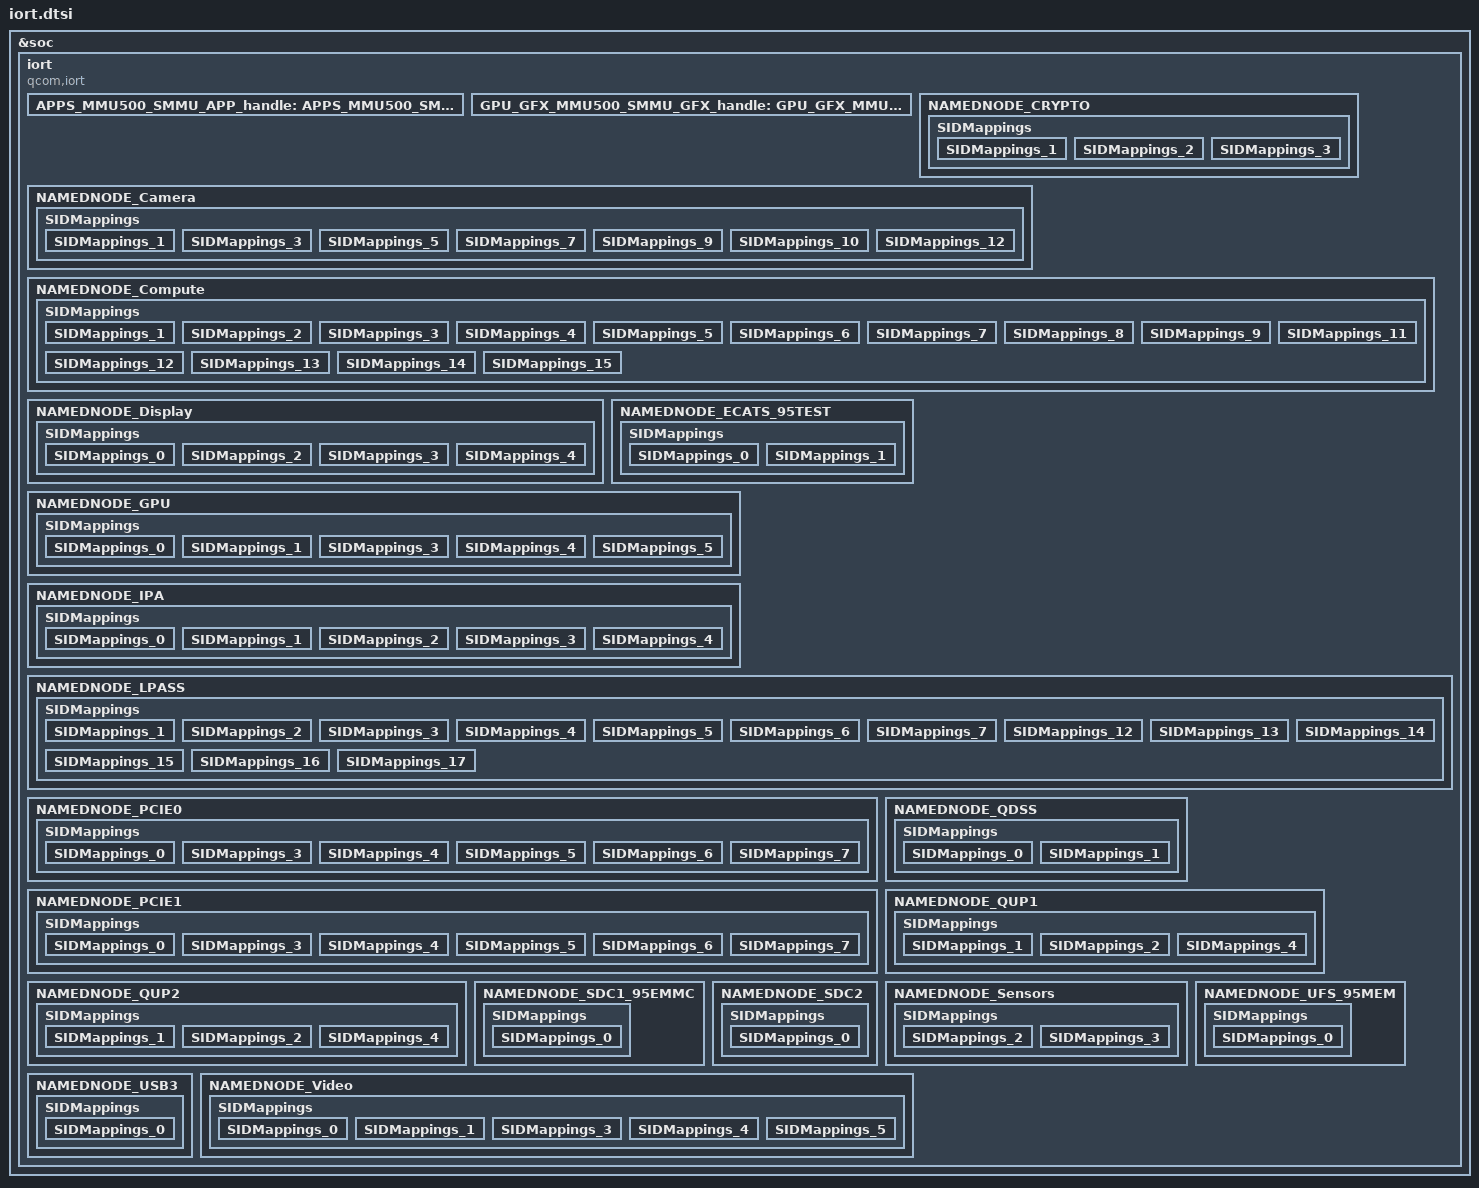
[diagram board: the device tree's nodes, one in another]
/** SMMU IORT Device Tree for milos_1.0.

This file is automatically generated.
SMMU Base Address and Span information based on Chip Version: milos_v1.0_p3q2r36_F02.
Interrupt information based on Interrupt Map Version: milos_v1.0_p3q1r23_09_22_DV_Patch.
SMMU SID Mappings based on http://ipcatalog.qualcomm.com/hsr/3393 - Milos_SID_Sheet.xlsx Version 6.0.

Copyright (c) 2023 Qualcomm Technologies, Inc.
All Rights Reserved.
Confidential and Proprietary - Qualcomm Technologies, Inc.
*/

#include <iort_defines.h>
&soc{
  iort {
    compatible = "qcom,iort";
    Signature = <0x54524F49>;
    Revision = <1>;
    Checksum = <0>;
    OEMID = ACPI_OEM_ID;
    OEMTableID = <ACPI_OEM_TABLE_ID>;
    OEMRevision = <ACPI_OEM_REVISION>;
    CreatorID = <ACPI_CREATOR_ID>;
    CreatorRevision = <ACPI_CREATOR_REVISION>;
    NumberofIORTNodes = <21>;
    Reserved = <0>;
    instance_handles = < &APPS_MMU500_SMMU_APP_handle  &GPU_GFX_MMU500_SMMU_GFX_handle >;
    
    APPS_MMU500_SMMU_APP_handle:APPS_MMU500_SMMU_APP {
      Type = <3>;
      Revision = <1>;
      Reserved = <0>;
      NumberofMappings = <0>;
      BaseAddress = <0x15000000>; 
      Span = <0x00080000>; 
      Flags = <3>;
      Model = <3>;
      NumContextInterrupts = <96>;
      NumPMUInterrupts = <0>;
      NSGIRPT_GSIV = <97>;
      NSGIRPT_FLAGS = <0>;
      NSGCFGIRPT_GSIV = <0>;
      NSGCFGIRPT_FLAGS = <0>;
      ContextInterrupts = <129 130 131 132 133 134 135 136 137 138 139 140 141 142 143 144 145 146 147 148 149 150 213 214 215 216 217 218 219 220 221 222 223 224 347 348 349 350 351 352 353 354 355 356 357 358 359 360 361 362 363 364 365 366 367 368 369 370 371 372 373 374 375 376 377 427 428 429 430 431 432 433 434 435 436 437 438 439 440 441 450 451 444 453 738 455 456 457 721 722 723 724 725 726 727 728 >;
      ContextInterruptFlags = <0 0 0 0 0 0 0 0 0 0 0 0 0 0 0 0 0 0 0 0 0 0 0 0 0 0 0 0 0 0 0 0 0 0 0 0 0 0 0 0 0 0 0 0 0 0 0 0 0 0 0 0 0 0 0 0 0 0 0 0 0 0 0 0 0 0 0 0 0 0 0 0 0 0 0 0 0 0 0 0 0 0 0 0 0 0 0 0 0 0 0 0 0 0 0 0 >;
      PMUInterrupts = <0 >;
      PMUInterruptFlags = <0 >;
      SIDMAPPING =<0>;
      };
    GPU_GFX_MMU500_SMMU_GFX_handle:GPU_GFX_MMU500_SMMU_GFX {
      Type = <3>;
      Revision = <1>;
      Reserved = <0>;
      NumberofMappings = <0>;
      BaseAddress = <0x03da0000>; 
      Span = <0x00020000>; 
      Flags = <3>;
      Model = <3>;
      NumContextInterrupts = <25>;
      NumPMUInterrupts = <0>;
      NSGIRPT_GSIV = <705>;
      NSGIRPT_FLAGS = <0>;
      NSGCFGIRPT_GSIV = <0>;
      NSGCFGIRPT_FLAGS = <0>;
      ContextInterrupts = <709 710 711 712 713 714 715 716 717 718 719 454 508 606 607 608 609 691 693 696 697 698 700 701 731 >;
      ContextInterruptFlags = <0 0 0 0 0 0 0 0 0 0 0 0 0 0 0 0 0 0 0 0 0 0 0 0 0 >;
      PMUInterrupts = <0 >;
      PMUInterruptFlags = <0 >;
      SIDMAPPING =<0>;
      };
    
    
    NAMEDNODE_CRYPTO {
      Type = <1>;
      Revision = <1>;
      Reserved = <0>;
      NumberofMappings = <3>;
      NodeFlags = <0>;
      CacheCoherency = <0>;
      AllocationHints = <0>;
      Reserved1 = <0>;
      MemAccessFlags = <0>;
      DeviceMemAddressSize = <36>;
      DevObjectName = "CRYPTO";
      SIDMappings {
        SIDMappings_1 {
          InputBase = <(
              (IORT_WORLD_ID_NON_SECURE << IORT_WORLD_ID_SHIFT) |
              (IORT_DYNAMIC_MAPPING_NO << IORT_DYNAMIC_MAPPING_SHIFT) |
              (IORT_TRANSLATION_TYPE_NESTED << IORT_TRANSLATION_TYPE_SHIFT) |
              (1))>;
          NumIDs = <1>;
          OutputBase = <0x00000481>;
          Flags = <0>;
          OutputReference = <&APPS_MMU500_SMMU_APP_handle>;
        };
        SIDMappings_2 {
          InputBase = <(
              (IORT_WORLD_ID_NON_SECURE << IORT_WORLD_ID_SHIFT) |
              (IORT_DYNAMIC_MAPPING_NO << IORT_DYNAMIC_MAPPING_SHIFT) |
              (IORT_TRANSLATION_TYPE_NESTED << IORT_TRANSLATION_TYPE_SHIFT) |
              (2))>;
          NumIDs = <1>;
          OutputBase = <0x00000480>;
          Flags = <0>;
          OutputReference = <&APPS_MMU500_SMMU_APP_handle>;
        };
        SIDMappings_3 {
          InputBase = <(
              (IORT_WORLD_ID_NON_SECURE << IORT_WORLD_ID_SHIFT) |
              (IORT_DYNAMIC_MAPPING_NO << IORT_DYNAMIC_MAPPING_SHIFT) |
              (IORT_TRANSLATION_TYPE_NESTED << IORT_TRANSLATION_TYPE_SHIFT) |
              (3))>;
          NumIDs = <1>;
          OutputBase = <0x00000483>;
          Flags = <0>;
          OutputReference = <&APPS_MMU500_SMMU_APP_handle>;
        };
      };
    };
    NAMEDNODE_Camera {
      Type = <1>;
      Revision = <1>;
      Reserved = <0>;
      NumberofMappings = <7>;
      NodeFlags = <0>;
      CacheCoherency = <0>;
      AllocationHints = <0>;
      Reserved1 = <0>;
      MemAccessFlags = <0>;
      DeviceMemAddressSize = <36>;
      DevObjectName = "CAMERA";
      SIDMappings {
        SIDMappings_1 {
          InputBase = <(
              (IORT_WORLD_ID_NON_SECURE << IORT_WORLD_ID_SHIFT) |
              (IORT_DYNAMIC_MAPPING_NO << IORT_DYNAMIC_MAPPING_SHIFT) |
              (IORT_TRANSLATION_TYPE_NESTED << IORT_TRANSLATION_TYPE_SHIFT) |
              (1))>;
          NumIDs = <1>;
          OutputBase = <0x00a01840>;
          Flags = <0>;
          OutputReference = <&APPS_MMU500_SMMU_APP_handle>;
        };
        SIDMappings_3 {
          InputBase = <(
              (IORT_WORLD_ID_NON_SECURE << IORT_WORLD_ID_SHIFT) |
              (IORT_DYNAMIC_MAPPING_NO << IORT_DYNAMIC_MAPPING_SHIFT) |
              (IORT_TRANSLATION_TYPE_NESTED << IORT_TRANSLATION_TYPE_SHIFT) |
              (3))>;
          NumIDs = <1>;
          OutputBase = <0x00001800>;
          Flags = <0>;
          OutputReference = <&APPS_MMU500_SMMU_APP_handle>;
        };
        SIDMappings_5 {
          InputBase = <(
              (IORT_WORLD_ID_NON_SECURE << IORT_WORLD_ID_SHIFT) |
              (IORT_DYNAMIC_MAPPING_NO << IORT_DYNAMIC_MAPPING_SHIFT) |
              (IORT_TRANSLATION_TYPE_NESTED << IORT_TRANSLATION_TYPE_SHIFT) |
              (5))>;
          NumIDs = <1>;
          OutputBase = <0x00001820>;
          Flags = <0>;
          OutputReference = <&APPS_MMU500_SMMU_APP_handle>;
        };
        SIDMappings_7 {
          InputBase = <(
              (IORT_WORLD_ID_NON_SECURE << IORT_WORLD_ID_SHIFT) |
              (IORT_DYNAMIC_MAPPING_NO << IORT_DYNAMIC_MAPPING_SHIFT) |
              (IORT_TRANSLATION_TYPE_NESTED << IORT_TRANSLATION_TYPE_SHIFT) |
              (7))>;
          NumIDs = <1>;
          OutputBase = <0x00001900>;
          Flags = <0>;
          OutputReference = <&APPS_MMU500_SMMU_APP_handle>;
        };
        SIDMappings_9 {
          InputBase = <(
              (IORT_WORLD_ID_NON_SECURE << IORT_WORLD_ID_SHIFT) |
              (IORT_DYNAMIC_MAPPING_NO << IORT_DYNAMIC_MAPPING_SHIFT) |
              (IORT_TRANSLATION_TYPE_NESTED << IORT_TRANSLATION_TYPE_SHIFT) |
              (9))>;
          NumIDs = <1>;
          OutputBase = <0x00001920>;
          Flags = <0>;
          OutputReference = <&APPS_MMU500_SMMU_APP_handle>;
        };
        SIDMappings_10 {
          InputBase = <(
              (IORT_WORLD_ID_NON_SECURE << IORT_WORLD_ID_SHIFT) |
              (IORT_DYNAMIC_MAPPING_NO << IORT_DYNAMIC_MAPPING_SHIFT) |
              (IORT_TRANSLATION_TYPE_NESTED << IORT_TRANSLATION_TYPE_SHIFT) |
              (10))>;
          NumIDs = <1>;
          OutputBase = <0x00001940>;
          Flags = <0>;
          OutputReference = <&APPS_MMU500_SMMU_APP_handle>;
        };
        SIDMappings_12 {
          InputBase = <(
              (IORT_WORLD_ID_NON_SECURE << IORT_WORLD_ID_SHIFT) |
              (IORT_DYNAMIC_MAPPING_NO << IORT_DYNAMIC_MAPPING_SHIFT) |
              (IORT_TRANSLATION_TYPE_NESTED << IORT_TRANSLATION_TYPE_SHIFT) |
              (12))>;
          NumIDs = <1>;
          OutputBase = <0x00200880>;
          Flags = <0>;
          OutputReference = <&APPS_MMU500_SMMU_APP_handle>;
        };
      };
    };
    NAMEDNODE_Compute {
      Type = <1>;
      Revision = <1>;
      Reserved = <0>;
      NumberofMappings = <14>;
      NodeFlags = <0>;
      CacheCoherency = <0>;
      AllocationHints = <0>;
      Reserved1 = <0>;
      MemAccessFlags = <0>;
      DeviceMemAddressSize = <36>;
      DevObjectName = "COMPUTE";
      SIDMappings {
        SIDMappings_1 {
          InputBase = <(
              (IORT_WORLD_ID_NON_SECURE << IORT_WORLD_ID_SHIFT) |
              (IORT_DYNAMIC_MAPPING_NO << IORT_DYNAMIC_MAPPING_SHIFT) |
              (IORT_TRANSLATION_TYPE_NESTED << IORT_TRANSLATION_TYPE_SHIFT) |
              (1))>;
          NumIDs = <1>;
          OutputBase = <0x00000c01>;
          Flags = <0>;
          OutputReference = <&APPS_MMU500_SMMU_APP_handle>;
        };
        SIDMappings_2 {
          InputBase = <(
              (IORT_WORLD_ID_NON_SECURE << IORT_WORLD_ID_SHIFT) |
              (IORT_DYNAMIC_MAPPING_NO << IORT_DYNAMIC_MAPPING_SHIFT) |
              (IORT_TRANSLATION_TYPE_NESTED << IORT_TRANSLATION_TYPE_SHIFT) |
              (2))>;
          NumIDs = <1>;
          OutputBase = <0x00000c02>;
          Flags = <0>;
          OutputReference = <&APPS_MMU500_SMMU_APP_handle>;
        };
        SIDMappings_3 {
          InputBase = <(
              (IORT_WORLD_ID_NON_SECURE << IORT_WORLD_ID_SHIFT) |
              (IORT_DYNAMIC_MAPPING_NO << IORT_DYNAMIC_MAPPING_SHIFT) |
              (IORT_TRANSLATION_TYPE_NESTED << IORT_TRANSLATION_TYPE_SHIFT) |
              (3))>;
          NumIDs = <1>;
          OutputBase = <0x00000c03>;
          Flags = <0>;
          OutputReference = <&APPS_MMU500_SMMU_APP_handle>;
        };
        SIDMappings_4 {
          InputBase = <(
              (IORT_WORLD_ID_NON_SECURE << IORT_WORLD_ID_SHIFT) |
              (IORT_DYNAMIC_MAPPING_NO << IORT_DYNAMIC_MAPPING_SHIFT) |
              (IORT_TRANSLATION_TYPE_NESTED << IORT_TRANSLATION_TYPE_SHIFT) |
              (4))>;
          NumIDs = <1>;
          OutputBase = <0x00000c04>;
          Flags = <0>;
          OutputReference = <&APPS_MMU500_SMMU_APP_handle>;
        };
        SIDMappings_5 {
          InputBase = <(
              (IORT_WORLD_ID_NON_SECURE << IORT_WORLD_ID_SHIFT) |
              (IORT_DYNAMIC_MAPPING_NO << IORT_DYNAMIC_MAPPING_SHIFT) |
              (IORT_TRANSLATION_TYPE_NESTED << IORT_TRANSLATION_TYPE_SHIFT) |
              (5))>;
          NumIDs = <1>;
          OutputBase = <0x00000c05>;
          Flags = <0>;
          OutputReference = <&APPS_MMU500_SMMU_APP_handle>;
        };
        SIDMappings_6 {
          InputBase = <(
              (IORT_WORLD_ID_NON_SECURE << IORT_WORLD_ID_SHIFT) |
              (IORT_DYNAMIC_MAPPING_NO << IORT_DYNAMIC_MAPPING_SHIFT) |
              (IORT_TRANSLATION_TYPE_NESTED << IORT_TRANSLATION_TYPE_SHIFT) |
              (6))>;
          NumIDs = <1>;
          OutputBase = <0x00000c06>;
          Flags = <0>;
          OutputReference = <&APPS_MMU500_SMMU_APP_handle>;
        };
        SIDMappings_7 {
          InputBase = <(
              (IORT_WORLD_ID_NON_SECURE << IORT_WORLD_ID_SHIFT) |
              (IORT_DYNAMIC_MAPPING_NO << IORT_DYNAMIC_MAPPING_SHIFT) |
              (IORT_TRANSLATION_TYPE_NESTED << IORT_TRANSLATION_TYPE_SHIFT) |
              (7))>;
          NumIDs = <1>;
          OutputBase = <0x00000c07>;
          Flags = <0>;
          OutputReference = <&APPS_MMU500_SMMU_APP_handle>;
        };
        SIDMappings_8 {
          InputBase = <(
              (IORT_WORLD_ID_NON_SECURE << IORT_WORLD_ID_SHIFT) |
              (IORT_DYNAMIC_MAPPING_NO << IORT_DYNAMIC_MAPPING_SHIFT) |
              (IORT_TRANSLATION_TYPE_NESTED << IORT_TRANSLATION_TYPE_SHIFT) |
              (8))>;
          NumIDs = <1>;
          OutputBase = <0x00000c08>;
          Flags = <0>;
          OutputReference = <&APPS_MMU500_SMMU_APP_handle>;
        };
        SIDMappings_9 {
          InputBase = <(
              (IORT_WORLD_ID_NON_SECURE << IORT_WORLD_ID_SHIFT) |
              (IORT_DYNAMIC_MAPPING_NO << IORT_DYNAMIC_MAPPING_SHIFT) |
              (IORT_TRANSLATION_TYPE_NESTED << IORT_TRANSLATION_TYPE_SHIFT) |
              (9))>;
          NumIDs = <1>;
          OutputBase = <0x00000c09>;
          Flags = <0>;
          OutputReference = <&APPS_MMU500_SMMU_APP_handle>;
        };
        SIDMappings_11 {
          InputBase = <(
              (IORT_WORLD_ID_NON_SECURE << IORT_WORLD_ID_SHIFT) |
              (IORT_DYNAMIC_MAPPING_NO << IORT_DYNAMIC_MAPPING_SHIFT) |
              (IORT_TRANSLATION_TYPE_NESTED << IORT_TRANSLATION_TYPE_SHIFT) |
              (11))>;
          NumIDs = <1>;
          OutputBase = <0x00000c0b>;
          Flags = <0>;
          OutputReference = <&APPS_MMU500_SMMU_APP_handle>;
        };
        SIDMappings_12 {
          InputBase = <(
              (IORT_WORLD_ID_NON_SECURE << IORT_WORLD_ID_SHIFT) |
              (IORT_DYNAMIC_MAPPING_NO << IORT_DYNAMIC_MAPPING_SHIFT) |
              (IORT_TRANSLATION_TYPE_NESTED << IORT_TRANSLATION_TYPE_SHIFT) |
              (12))>;
          NumIDs = <1>;
          OutputBase = <0x00000c0c>;
          Flags = <0>;
          OutputReference = <&APPS_MMU500_SMMU_APP_handle>;
        };
        SIDMappings_13 {
          InputBase = <(
              (IORT_WORLD_ID_NON_SECURE << IORT_WORLD_ID_SHIFT) |
              (IORT_DYNAMIC_MAPPING_NO << IORT_DYNAMIC_MAPPING_SHIFT) |
              (IORT_TRANSLATION_TYPE_NESTED << IORT_TRANSLATION_TYPE_SHIFT) |
              (13))>;
          NumIDs = <1>;
          OutputBase = <0x00000c0d>;
          Flags = <0>;
          OutputReference = <&APPS_MMU500_SMMU_APP_handle>;
        };
        SIDMappings_14 {
          InputBase = <(
              (IORT_WORLD_ID_NON_SECURE << IORT_WORLD_ID_SHIFT) |
              (IORT_DYNAMIC_MAPPING_NO << IORT_DYNAMIC_MAPPING_SHIFT) |
              (IORT_TRANSLATION_TYPE_NESTED << IORT_TRANSLATION_TYPE_SHIFT) |
              (14))>;
          NumIDs = <1>;
          OutputBase = <0x00000c0e>;
          Flags = <0>;
          OutputReference = <&APPS_MMU500_SMMU_APP_handle>;
        };
        SIDMappings_15 {
          InputBase = <(
              (IORT_WORLD_ID_NON_SECURE << IORT_WORLD_ID_SHIFT) |
              (IORT_DYNAMIC_MAPPING_NO << IORT_DYNAMIC_MAPPING_SHIFT) |
              (IORT_TRANSLATION_TYPE_NESTED << IORT_TRANSLATION_TYPE_SHIFT) |
              (15))>;
          NumIDs = <1>;
          OutputBase = <0x00000c0f>;
          Flags = <0>;
          OutputReference = <&APPS_MMU500_SMMU_APP_handle>;
        };
      };
    };
    NAMEDNODE_Display {
      Type = <1>;
      Revision = <1>;
      Reserved = <0>;
      NumberofMappings = <4>;
      NodeFlags = <0>;
      CacheCoherency = <0>;
      AllocationHints = <0>;
      Reserved1 = <0>;
      MemAccessFlags = <0>;
      DeviceMemAddressSize = <36>;
      DevObjectName = "DISPLAY";
      SIDMappings {
        SIDMappings_0 {
          InputBase = <(
              (IORT_WORLD_ID_NON_SECURE << IORT_WORLD_ID_SHIFT) |
              (IORT_DYNAMIC_MAPPING_NO << IORT_DYNAMIC_MAPPING_SHIFT) |
              (IORT_TRANSLATION_TYPE_NESTED << IORT_TRANSLATION_TYPE_SHIFT) |
              (0))>;
          NumIDs = <1>;
          OutputBase = <0x00021c00>;
          Flags = <0>;
          OutputReference = <&APPS_MMU500_SMMU_APP_handle>;
        };
        SIDMappings_2 {
          InputBase = <(
              (IORT_WORLD_ID_NON_SECURE << IORT_WORLD_ID_SHIFT) |
              (IORT_DYNAMIC_MAPPING_YES_DEFAULT << IORT_DYNAMIC_MAPPING_SHIFT) |
              (IORT_TRANSLATION_TYPE_NESTED << IORT_TRANSLATION_TYPE_SHIFT) |
              (2))>;
          NumIDs = <1>;
          OutputBase = <0x00001c01>;
          Flags = <0>;
          OutputReference = <&APPS_MMU500_SMMU_APP_handle>;
        };
        SIDMappings_3 {
          InputBase = <(
              (IORT_WORLD_ID_NON_SECURE << IORT_WORLD_ID_SHIFT) |
              (IORT_DYNAMIC_MAPPING_NO << IORT_DYNAMIC_MAPPING_SHIFT) |
              (IORT_TRANSLATION_TYPE_NESTED << IORT_TRANSLATION_TYPE_SHIFT) |
              (3))>;
          NumIDs = <1>;
          OutputBase = <0x00001c03>;
          Flags = <0>;
          OutputReference = <&APPS_MMU500_SMMU_APP_handle>;
        };
        SIDMappings_4 {
          InputBase = <(
              (IORT_WORLD_ID_NON_SECURE << IORT_WORLD_ID_SHIFT) |
              (IORT_DYNAMIC_MAPPING_NO << IORT_DYNAMIC_MAPPING_SHIFT) |
              (IORT_TRANSLATION_TYPE_NESTED << IORT_TRANSLATION_TYPE_SHIFT) |
              (4))>;
          NumIDs = <1>;
          OutputBase = <0x00021c04>;
          Flags = <0>;
          OutputReference = <&APPS_MMU500_SMMU_APP_handle>;
        };
      };
    };
    NAMEDNODE_ECATS_95TEST {
      Type = <1>;
      Revision = <1>;
      Reserved = <0>;
      NumberofMappings = <2>;
      NodeFlags = <0>;
      CacheCoherency = <0>;
      AllocationHints = <0>;
      Reserved1 = <0>;
      MemAccessFlags = <0>;
      DeviceMemAddressSize = <36>;
      DevObjectName = "ECATS_TEST";
      SIDMappings {
        SIDMappings_0 {
          InputBase = <(
              (IORT_WORLD_ID_NON_SECURE << IORT_WORLD_ID_SHIFT) |
              (IORT_DYNAMIC_MAPPING_NO << IORT_DYNAMIC_MAPPING_SHIFT) |
              (IORT_TRANSLATION_TYPE_NESTED << IORT_TRANSLATION_TYPE_SHIFT) |
              (0))>;
          NumIDs = <1>;
          OutputBase = <0x00000400>;
          Flags = <0>;
          OutputReference = <&APPS_MMU500_SMMU_APP_handle>;
        };
        SIDMappings_1 {
          InputBase = <(
              (IORT_WORLD_ID_NON_SECURE << IORT_WORLD_ID_SHIFT) |
              (IORT_DYNAMIC_MAPPING_NO << IORT_DYNAMIC_MAPPING_SHIFT) |
              (IORT_TRANSLATION_TYPE_NESTED << IORT_TRANSLATION_TYPE_SHIFT) |
              (1))>;
          NumIDs = <1>;
          OutputBase = <0x00000401>;
          Flags = <0>;
          OutputReference = <&APPS_MMU500_SMMU_APP_handle>;
        };
      };
    };
    NAMEDNODE_GPU {
      Type = <1>;
      Revision = <1>;
      Reserved = <0>;
      NumberofMappings = <5>;
      NodeFlags = <0>;
      CacheCoherency = <0>;
      AllocationHints = <0>;
      Reserved1 = <0>;
      MemAccessFlags = <0>;
      DeviceMemAddressSize = <36>;
      DevObjectName = "GPU";
      SIDMappings {
        SIDMappings_0 {
          InputBase = <(
              (IORT_WORLD_ID_NON_SECURE << IORT_WORLD_ID_SHIFT) |
              (IORT_DYNAMIC_MAPPING_NO << IORT_DYNAMIC_MAPPING_SHIFT) |
              (IORT_TRANSLATION_TYPE_NESTED << IORT_TRANSLATION_TYPE_SHIFT) |
              (0))>;
          NumIDs = <1>;
          OutputBase = <0x00000000>;
          Flags = <0>;
          OutputReference = <&GPU_GFX_MMU500_SMMU_GFX_handle>;
        };
        SIDMappings_1 {
          InputBase = <(
              (IORT_WORLD_ID_NON_SECURE << IORT_WORLD_ID_SHIFT) |
              (IORT_DYNAMIC_MAPPING_NO << IORT_DYNAMIC_MAPPING_SHIFT) |
              (IORT_TRANSLATION_TYPE_NESTED << IORT_TRANSLATION_TYPE_SHIFT) |
              (1))>;
          NumIDs = <1>;
          OutputBase = <0x00000002>;
          Flags = <0>;
          OutputReference = <&GPU_GFX_MMU500_SMMU_GFX_handle>;
        };
        SIDMappings_3 {
          InputBase = <(
              (IORT_WORLD_ID_NON_SECURE << IORT_WORLD_ID_SHIFT) |
              (IORT_DYNAMIC_MAPPING_NO << IORT_DYNAMIC_MAPPING_SHIFT) |
              (IORT_TRANSLATION_TYPE_NESTED << IORT_TRANSLATION_TYPE_SHIFT) |
              (3))>;
          NumIDs = <1>;
          OutputBase = <0x00000004>;
          Flags = <0>;
          OutputReference = <&GPU_GFX_MMU500_SMMU_GFX_handle>;
        };
        SIDMappings_4 {
          InputBase = <(
              (IORT_WORLD_ID_NON_SECURE << IORT_WORLD_ID_SHIFT) |
              (IORT_DYNAMIC_MAPPING_NO << IORT_DYNAMIC_MAPPING_SHIFT) |
              (IORT_TRANSLATION_TYPE_NESTED << IORT_TRANSLATION_TYPE_SHIFT) |
              (4))>;
          NumIDs = <1>;
          OutputBase = <0x00000005>;
          Flags = <0>;
          OutputReference = <&GPU_GFX_MMU500_SMMU_GFX_handle>;
        };
        SIDMappings_5 {
          InputBase = <(
              (IORT_WORLD_ID_NON_SECURE << IORT_WORLD_ID_SHIFT) |
              (IORT_DYNAMIC_MAPPING_NO << IORT_DYNAMIC_MAPPING_SHIFT) |
              (IORT_TRANSLATION_TYPE_NESTED << IORT_TRANSLATION_TYPE_SHIFT) |
              (5))>;
          NumIDs = <1>;
          OutputBase = <0x00000007>;
          Flags = <0>;
          OutputReference = <&GPU_GFX_MMU500_SMMU_GFX_handle>;
        };
      };
    };
    NAMEDNODE_IPA {
      Type = <1>;
      Revision = <1>;
      Reserved = <0>;
      NumberofMappings = <5>;
      NodeFlags = <0>;
      CacheCoherency = <0>;
      AllocationHints = <0>;
      Reserved1 = <0>;
      MemAccessFlags = <0>;
      DeviceMemAddressSize = <36>;
      DevObjectName = "IPA";
      SIDMappings {
        SIDMappings_0 {
          InputBase = <(
              (IORT_WORLD_ID_NON_SECURE << IORT_WORLD_ID_SHIFT) |
              (IORT_DYNAMIC_MAPPING_NO << IORT_DYNAMIC_MAPPING_SHIFT) |
              (IORT_TRANSLATION_TYPE_NESTED << IORT_TRANSLATION_TYPE_SHIFT) |
              (0))>;
          NumIDs = <1>;
          OutputBase = <0x000004a0>;
          Flags = <0>;
          OutputReference = <&APPS_MMU500_SMMU_APP_handle>;
        };
        SIDMappings_1 {
          InputBase = <(
              (IORT_WORLD_ID_NON_SECURE << IORT_WORLD_ID_SHIFT) |
              (IORT_DYNAMIC_MAPPING_NO << IORT_DYNAMIC_MAPPING_SHIFT) |
              (IORT_TRANSLATION_TYPE_NESTED << IORT_TRANSLATION_TYPE_SHIFT) |
              (1))>;
          NumIDs = <1>;
          OutputBase = <0x000004a1>;
          Flags = <0>;
          OutputReference = <&APPS_MMU500_SMMU_APP_handle>;
        };
        SIDMappings_2 {
          InputBase = <(
              (IORT_WORLD_ID_NON_SECURE << IORT_WORLD_ID_SHIFT) |
              (IORT_DYNAMIC_MAPPING_NO << IORT_DYNAMIC_MAPPING_SHIFT) |
              (IORT_TRANSLATION_TYPE_NESTED << IORT_TRANSLATION_TYPE_SHIFT) |
              (2))>;
          NumIDs = <1>;
          OutputBase = <0x000004a2>;
          Flags = <0>;
          OutputReference = <&APPS_MMU500_SMMU_APP_handle>;
        };
        SIDMappings_3 {
          InputBase = <(
              (IORT_WORLD_ID_NON_SECURE << IORT_WORLD_ID_SHIFT) |
              (IORT_DYNAMIC_MAPPING_NO << IORT_DYNAMIC_MAPPING_SHIFT) |
              (IORT_TRANSLATION_TYPE_NESTED << IORT_TRANSLATION_TYPE_SHIFT) |
              (3))>;
          NumIDs = <1>;
          OutputBase = <0x000004a3>;
          Flags = <0>;
          OutputReference = <&APPS_MMU500_SMMU_APP_handle>;
        };
        SIDMappings_4 {
          InputBase = <(
              (IORT_WORLD_ID_NON_SECURE << IORT_WORLD_ID_SHIFT) |
              (IORT_DYNAMIC_MAPPING_NO << IORT_DYNAMIC_MAPPING_SHIFT) |
              (IORT_TRANSLATION_TYPE_NESTED << IORT_TRANSLATION_TYPE_SHIFT) |
              (4))>;
          NumIDs = <1>;
          OutputBase = <0x000004a4>;
          Flags = <0>;
          OutputReference = <&APPS_MMU500_SMMU_APP_handle>;
        };
      };
    };
    NAMEDNODE_LPASS {
      Type = <1>;
      Revision = <1>;
      Reserved = <0>;
      NumberofMappings = <13>;
      NodeFlags = <0>;
      CacheCoherency = <0>;
      AllocationHints = <0>;
      Reserved1 = <0>;
      MemAccessFlags = <0>;
      DeviceMemAddressSize = <36>;
      DevObjectName = "LPASS";
      SIDMappings {
        SIDMappings_1 {
          InputBase = <(
              (IORT_WORLD_ID_NON_SECURE << IORT_WORLD_ID_SHIFT) |
              (IORT_DYNAMIC_MAPPING_NO << IORT_DYNAMIC_MAPPING_SHIFT) |
              (IORT_TRANSLATION_TYPE_NESTED << IORT_TRANSLATION_TYPE_SHIFT) |
              (1))>;
          NumIDs = <1>;
          OutputBase = <0x00001001>;
          Flags = <0>;
          OutputReference = <&APPS_MMU500_SMMU_APP_handle>;
        };
        SIDMappings_2 {
          InputBase = <(
              (IORT_WORLD_ID_NON_SECURE << IORT_WORLD_ID_SHIFT) |
              (IORT_DYNAMIC_MAPPING_NO << IORT_DYNAMIC_MAPPING_SHIFT) |
              (IORT_TRANSLATION_TYPE_NESTED << IORT_TRANSLATION_TYPE_SHIFT) |
              (2))>;
          NumIDs = <1>;
          OutputBase = <0x00001003>;
          Flags = <0>;
          OutputReference = <&APPS_MMU500_SMMU_APP_handle>;
        };
        SIDMappings_3 {
          InputBase = <(
              (IORT_WORLD_ID_NON_SECURE << IORT_WORLD_ID_SHIFT) |
              (IORT_DYNAMIC_MAPPING_NO << IORT_DYNAMIC_MAPPING_SHIFT) |
              (IORT_TRANSLATION_TYPE_NESTED << IORT_TRANSLATION_TYPE_SHIFT) |
              (3))>;
          NumIDs = <1>;
          OutputBase = <0x00001004>;
          Flags = <0>;
          OutputReference = <&APPS_MMU500_SMMU_APP_handle>;
        };
        SIDMappings_4 {
          InputBase = <(
              (IORT_WORLD_ID_NON_SECURE << IORT_WORLD_ID_SHIFT) |
              (IORT_DYNAMIC_MAPPING_NO << IORT_DYNAMIC_MAPPING_SHIFT) |
              (IORT_TRANSLATION_TYPE_NESTED << IORT_TRANSLATION_TYPE_SHIFT) |
              (4))>;
          NumIDs = <1>;
          OutputBase = <0x00001005>;
          Flags = <0>;
          OutputReference = <&APPS_MMU500_SMMU_APP_handle>;
        };
        SIDMappings_5 {
          InputBase = <(
              (IORT_WORLD_ID_NON_SECURE << IORT_WORLD_ID_SHIFT) |
              (IORT_DYNAMIC_MAPPING_NO << IORT_DYNAMIC_MAPPING_SHIFT) |
              (IORT_TRANSLATION_TYPE_NESTED << IORT_TRANSLATION_TYPE_SHIFT) |
              (5))>;
          NumIDs = <1>;
          OutputBase = <0x00001006>;
          Flags = <0>;
          OutputReference = <&APPS_MMU500_SMMU_APP_handle>;
        };
        SIDMappings_6 {
          InputBase = <(
              (IORT_WORLD_ID_NON_SECURE << IORT_WORLD_ID_SHIFT) |
              (IORT_DYNAMIC_MAPPING_NO << IORT_DYNAMIC_MAPPING_SHIFT) |
              (IORT_TRANSLATION_TYPE_NESTED << IORT_TRANSLATION_TYPE_SHIFT) |
              (6))>;
          NumIDs = <1>;
          OutputBase = <0x00001007>;
          Flags = <0>;
          OutputReference = <&APPS_MMU500_SMMU_APP_handle>;
        };
        SIDMappings_7 {
          InputBase = <(
              (IORT_WORLD_ID_NON_SECURE << IORT_WORLD_ID_SHIFT) |
              (IORT_DYNAMIC_MAPPING_NO << IORT_DYNAMIC_MAPPING_SHIFT) |
              (IORT_TRANSLATION_TYPE_NESTED << IORT_TRANSLATION_TYPE_SHIFT) |
              (7))>;
          NumIDs = <1>;
          OutputBase = <0x0000100f>;
          Flags = <0>;
          OutputReference = <&APPS_MMU500_SMMU_APP_handle>;
        };
        SIDMappings_12 {
          InputBase = <(
              (IORT_WORLD_ID_NON_SECURE << IORT_WORLD_ID_SHIFT) |
              (IORT_DYNAMIC_MAPPING_NO << IORT_DYNAMIC_MAPPING_SHIFT) |
              (IORT_TRANSLATION_TYPE_NESTED << IORT_TRANSLATION_TYPE_SHIFT) |
              (12))>;
          NumIDs = <1>;
          OutputBase = <0x00001061>;
          Flags = <0>;
          OutputReference = <&APPS_MMU500_SMMU_APP_handle>;
        };
        SIDMappings_13 {
          InputBase = <(
              (IORT_WORLD_ID_NON_SECURE << IORT_WORLD_ID_SHIFT) |
              (IORT_DYNAMIC_MAPPING_NO << IORT_DYNAMIC_MAPPING_SHIFT) |
              (IORT_TRANSLATION_TYPE_NESTED << IORT_TRANSLATION_TYPE_SHIFT) |
              (13))>;
          NumIDs = <1>;
          OutputBase = <0x00001063>;
          Flags = <0>;
          OutputReference = <&APPS_MMU500_SMMU_APP_handle>;
        };
        SIDMappings_14 {
          InputBase = <(
              (IORT_WORLD_ID_NON_SECURE << IORT_WORLD_ID_SHIFT) |
              (IORT_DYNAMIC_MAPPING_NO << IORT_DYNAMIC_MAPPING_SHIFT) |
              (IORT_TRANSLATION_TYPE_NESTED << IORT_TRANSLATION_TYPE_SHIFT) |
              (14))>;
          NumIDs = <1>;
          OutputBase = <0x00001064>;
          Flags = <0>;
          OutputReference = <&APPS_MMU500_SMMU_APP_handle>;
        };
        SIDMappings_15 {
          InputBase = <(
              (IORT_WORLD_ID_NON_SECURE << IORT_WORLD_ID_SHIFT) |
              (IORT_DYNAMIC_MAPPING_NO << IORT_DYNAMIC_MAPPING_SHIFT) |
              (IORT_TRANSLATION_TYPE_NESTED << IORT_TRANSLATION_TYPE_SHIFT) |
              (15))>;
          NumIDs = <1>;
          OutputBase = <0x00001065>;
          Flags = <0>;
          OutputReference = <&APPS_MMU500_SMMU_APP_handle>;
        };
        SIDMappings_16 {
          InputBase = <(
              (IORT_WORLD_ID_NON_SECURE << IORT_WORLD_ID_SHIFT) |
              (IORT_DYNAMIC_MAPPING_NO << IORT_DYNAMIC_MAPPING_SHIFT) |
              (IORT_TRANSLATION_TYPE_NESTED << IORT_TRANSLATION_TYPE_SHIFT) |
              (16))>;
          NumIDs = <1>;
          OutputBase = <0x00001066>;
          Flags = <0>;
          OutputReference = <&APPS_MMU500_SMMU_APP_handle>;
        };
        SIDMappings_17 {
          InputBase = <(
              (IORT_WORLD_ID_NON_SECURE << IORT_WORLD_ID_SHIFT) |
              (IORT_DYNAMIC_MAPPING_NO << IORT_DYNAMIC_MAPPING_SHIFT) |
              (IORT_TRANSLATION_TYPE_NESTED << IORT_TRANSLATION_TYPE_SHIFT) |
              (17))>;
          NumIDs = <1>;
          OutputBase = <0x00001067>;
          Flags = <0>;
          OutputReference = <&APPS_MMU500_SMMU_APP_handle>;
        };
      };
    };
    NAMEDNODE_PCIE0 {
      Type = <1>;
      Revision = <1>;
      Reserved = <0>;
      NumberofMappings = <6>;
      NodeFlags = <0>;
      CacheCoherency = <0>;
      AllocationHints = <0>;
      Reserved1 = <0>;
      MemAccessFlags = <0>;
      DeviceMemAddressSize = <36>;
      DevObjectName = "PCIE0";
      SIDMappings {
        SIDMappings_0 {
          InputBase = <(
              (IORT_WORLD_ID_NON_SECURE << IORT_WORLD_ID_SHIFT) |
              (IORT_DYNAMIC_MAPPING_NO << IORT_DYNAMIC_MAPPING_SHIFT) |
              (IORT_TRANSLATION_TYPE_NESTED << IORT_TRANSLATION_TYPE_SHIFT) |
              (0))>;
          NumIDs = <1>;
          OutputBase = <0x00011400>;
          Flags = <0>;
          OutputReference = <&APPS_MMU500_SMMU_APP_handle>;
        };
        SIDMappings_3 {
          InputBase = <(
              (IORT_WORLD_ID_NON_SECURE << IORT_WORLD_ID_SHIFT) |
              (IORT_DYNAMIC_MAPPING_NO << IORT_DYNAMIC_MAPPING_SHIFT) |
              (IORT_TRANSLATION_TYPE_NESTED << IORT_TRANSLATION_TYPE_SHIFT) |
              (3))>;
          NumIDs = <1>;
          OutputBase = <0x00031404>;
          Flags = <0>;
          OutputReference = <&APPS_MMU500_SMMU_APP_handle>;
        };
        SIDMappings_4 {
          InputBase = <(
              (IORT_WORLD_ID_NON_SECURE << IORT_WORLD_ID_SHIFT) |
              (IORT_DYNAMIC_MAPPING_NO << IORT_DYNAMIC_MAPPING_SHIFT) |
              (IORT_TRANSLATION_TYPE_NESTED << IORT_TRANSLATION_TYPE_SHIFT) |
              (4))>;
          NumIDs = <1>;
          OutputBase = <0x00071408>;
          Flags = <0>;
          OutputReference = <&APPS_MMU500_SMMU_APP_handle>;
        };
        SIDMappings_5 {
          InputBase = <(
              (IORT_WORLD_ID_NON_SECURE << IORT_WORLD_ID_SHIFT) |
              (IORT_DYNAMIC_MAPPING_NO << IORT_DYNAMIC_MAPPING_SHIFT) |
              (IORT_TRANSLATION_TYPE_NESTED << IORT_TRANSLATION_TYPE_SHIFT) |
              (5))>;
          NumIDs = <1>;
          OutputBase = <0x000f1410>;
          Flags = <0>;
          OutputReference = <&APPS_MMU500_SMMU_APP_handle>;
        };
        SIDMappings_6 {
          InputBase = <(
              (IORT_WORLD_ID_NON_SECURE << IORT_WORLD_ID_SHIFT) |
              (IORT_DYNAMIC_MAPPING_NO << IORT_DYNAMIC_MAPPING_SHIFT) |
              (IORT_TRANSLATION_TYPE_NESTED << IORT_TRANSLATION_TYPE_SHIFT) |
              (6))>;
          NumIDs = <1>;
          OutputBase = <0x001f1420>;
          Flags = <0>;
          OutputReference = <&APPS_MMU500_SMMU_APP_handle>;
        };
        SIDMappings_7 {
          InputBase = <(
              (IORT_WORLD_ID_NON_SECURE << IORT_WORLD_ID_SHIFT) |
              (IORT_DYNAMIC_MAPPING_NO << IORT_DYNAMIC_MAPPING_SHIFT) |
              (IORT_TRANSLATION_TYPE_NESTED << IORT_TRANSLATION_TYPE_SHIFT) |
              (7))>;
          NumIDs = <1>;
          OutputBase = <0x003f1440>;
          Flags = <0>;
          OutputReference = <&APPS_MMU500_SMMU_APP_handle>;
        };
      };
    };
    NAMEDNODE_PCIE1 {
      Type = <1>;
      Revision = <1>;
      Reserved = <0>;
      NumberofMappings = <6>;
      NodeFlags = <0>;
      CacheCoherency = <0>;
      AllocationHints = <0>;
      Reserved1 = <0>;
      MemAccessFlags = <0>;
      DeviceMemAddressSize = <36>;
      DevObjectName = "PCIE1";
      SIDMappings {
        SIDMappings_0 {
          InputBase = <(
              (IORT_WORLD_ID_NON_SECURE << IORT_WORLD_ID_SHIFT) |
              (IORT_DYNAMIC_MAPPING_NO << IORT_DYNAMIC_MAPPING_SHIFT) |
              (IORT_TRANSLATION_TYPE_NESTED << IORT_TRANSLATION_TYPE_SHIFT) |
              (0))>;
          NumIDs = <1>;
          OutputBase = <0x00011480>;
          Flags = <0>;
          OutputReference = <&APPS_MMU500_SMMU_APP_handle>;
        };
        SIDMappings_3 {
          InputBase = <(
              (IORT_WORLD_ID_NON_SECURE << IORT_WORLD_ID_SHIFT) |
              (IORT_DYNAMIC_MAPPING_NO << IORT_DYNAMIC_MAPPING_SHIFT) |
              (IORT_TRANSLATION_TYPE_NESTED << IORT_TRANSLATION_TYPE_SHIFT) |
              (3))>;
          NumIDs = <1>;
          OutputBase = <0x00031484>;
          Flags = <0>;
          OutputReference = <&APPS_MMU500_SMMU_APP_handle>;
        };
        SIDMappings_4 {
          InputBase = <(
              (IORT_WORLD_ID_NON_SECURE << IORT_WORLD_ID_SHIFT) |
              (IORT_DYNAMIC_MAPPING_NO << IORT_DYNAMIC_MAPPING_SHIFT) |
              (IORT_TRANSLATION_TYPE_NESTED << IORT_TRANSLATION_TYPE_SHIFT) |
              (4))>;
          NumIDs = <1>;
          OutputBase = <0x00071488>;
          Flags = <0>;
          OutputReference = <&APPS_MMU500_SMMU_APP_handle>;
        };
        SIDMappings_5 {
          InputBase = <(
              (IORT_WORLD_ID_NON_SECURE << IORT_WORLD_ID_SHIFT) |
              (IORT_DYNAMIC_MAPPING_NO << IORT_DYNAMIC_MAPPING_SHIFT) |
              (IORT_TRANSLATION_TYPE_NESTED << IORT_TRANSLATION_TYPE_SHIFT) |
              (5))>;
          NumIDs = <1>;
          OutputBase = <0x000f1490>;
          Flags = <0>;
          OutputReference = <&APPS_MMU500_SMMU_APP_handle>;
        };
        SIDMappings_6 {
          InputBase = <(
              (IORT_WORLD_ID_NON_SECURE << IORT_WORLD_ID_SHIFT) |
              (IORT_DYNAMIC_MAPPING_NO << IORT_DYNAMIC_MAPPING_SHIFT) |
              (IORT_TRANSLATION_TYPE_NESTED << IORT_TRANSLATION_TYPE_SHIFT) |
              (6))>;
          NumIDs = <1>;
          OutputBase = <0x001f14a0>;
          Flags = <0>;
          OutputReference = <&APPS_MMU500_SMMU_APP_handle>;
        };
        SIDMappings_7 {
          InputBase = <(
              (IORT_WORLD_ID_NON_SECURE << IORT_WORLD_ID_SHIFT) |
              (IORT_DYNAMIC_MAPPING_NO << IORT_DYNAMIC_MAPPING_SHIFT) |
              (IORT_TRANSLATION_TYPE_NESTED << IORT_TRANSLATION_TYPE_SHIFT) |
              (7))>;
          NumIDs = <1>;
          OutputBase = <0x003f14c0>;
          Flags = <0>;
          OutputReference = <&APPS_MMU500_SMMU_APP_handle>;
        };
      };
    };
    NAMEDNODE_QDSS {
      Type = <1>;
      Revision = <1>;
      Reserved = <0>;
      NumberofMappings = <2>;
      NodeFlags = <0>;
      CacheCoherency = <0>;
      AllocationHints = <0>;
      Reserved1 = <0>;
      MemAccessFlags = <0>;
      DeviceMemAddressSize = <36>;
      DevObjectName = "QDSS";
      SIDMappings {
        SIDMappings_0 {
          InputBase = <(
              (IORT_WORLD_ID_NON_SECURE << IORT_WORLD_ID_SHIFT) |
              (IORT_DYNAMIC_MAPPING_NO << IORT_DYNAMIC_MAPPING_SHIFT) |
              (IORT_TRANSLATION_TYPE_NESTED << IORT_TRANSLATION_TYPE_SHIFT) |
              (0))>;
          NumIDs = <1>;
          OutputBase = <0x002004c0>;
          Flags = <0>;
          OutputReference = <&APPS_MMU500_SMMU_APP_handle>;
        };
        SIDMappings_1 {
          InputBase = <(
              (IORT_WORLD_ID_NON_SECURE << IORT_WORLD_ID_SHIFT) |
              (IORT_DYNAMIC_MAPPING_NO << IORT_DYNAMIC_MAPPING_SHIFT) |
              (IORT_TRANSLATION_TYPE_NESTED << IORT_TRANSLATION_TYPE_SHIFT) |
              (1))>;
          NumIDs = <1>;
          OutputBase = <0x00000500>;
          Flags = <0>;
          OutputReference = <&APPS_MMU500_SMMU_APP_handle>;
        };
      };
    };
    NAMEDNODE_QUP1 {
      Type = <1>;
      Revision = <1>;
      Reserved = <0>;
      NumberofMappings = <3>;
      NodeFlags = <0>;
      CacheCoherency = <0>;
      AllocationHints = <0>;
      Reserved1 = <0>;
      MemAccessFlags = <0>;
      DeviceMemAddressSize = <36>;
      DevObjectName = "QUP1";
      SIDMappings {
        SIDMappings_1 {
          InputBase = <(
              (IORT_WORLD_ID_NON_SECURE << IORT_WORLD_ID_SHIFT) |
              (IORT_DYNAMIC_MAPPING_NO << IORT_DYNAMIC_MAPPING_SHIFT) |
              (IORT_TRANSLATION_TYPE_NESTED << IORT_TRANSLATION_TYPE_SHIFT) |
              (1))>;
          NumIDs = <1>;
          OutputBase = <0x00000576>;
          Flags = <0>;
          OutputReference = <&APPS_MMU500_SMMU_APP_handle>;
        };
        SIDMappings_2 {
          InputBase = <(
              (IORT_WORLD_ID_NON_SECURE << IORT_WORLD_ID_SHIFT) |
              (IORT_DYNAMIC_MAPPING_NO << IORT_DYNAMIC_MAPPING_SHIFT) |
              (IORT_TRANSLATION_TYPE_NESTED << IORT_TRANSLATION_TYPE_SHIFT) |
              (2))>;
          NumIDs = <1>;
          OutputBase = <0x00000578>;
          Flags = <0>;
          OutputReference = <&APPS_MMU500_SMMU_APP_handle>;
        };
        SIDMappings_4 {
          InputBase = <(
              (IORT_WORLD_ID_NON_SECURE << IORT_WORLD_ID_SHIFT) |
              (IORT_DYNAMIC_MAPPING_NO << IORT_DYNAMIC_MAPPING_SHIFT) |
              (IORT_TRANSLATION_TYPE_NESTED << IORT_TRANSLATION_TYPE_SHIFT) |
              (4))>;
          NumIDs = <1>;
          OutputBase = <0x00000563>;
          Flags = <0>;
          OutputReference = <&APPS_MMU500_SMMU_APP_handle>;
        };
      };
    };
    NAMEDNODE_QUP2 {
      Type = <1>;
      Revision = <1>;
      Reserved = <0>;
      NumberofMappings = <3>;
      NodeFlags = <0>;
      CacheCoherency = <0>;
      AllocationHints = <0>;
      Reserved1 = <0>;
      MemAccessFlags = <0>;
      DeviceMemAddressSize = <36>;
      DevObjectName = "QUP2";
      SIDMappings {
        SIDMappings_1 {
          InputBase = <(
              (IORT_WORLD_ID_NON_SECURE << IORT_WORLD_ID_SHIFT) |
              (IORT_DYNAMIC_MAPPING_NO << IORT_DYNAMIC_MAPPING_SHIFT) |
              (IORT_TRANSLATION_TYPE_NESTED << IORT_TRANSLATION_TYPE_SHIFT) |
              (1))>;
          NumIDs = <1>;
          OutputBase = <0x00000036>;
          Flags = <0>;
          OutputReference = <&APPS_MMU500_SMMU_APP_handle>;
        };
        SIDMappings_2 {
          InputBase = <(
              (IORT_WORLD_ID_NON_SECURE << IORT_WORLD_ID_SHIFT) |
              (IORT_DYNAMIC_MAPPING_NO << IORT_DYNAMIC_MAPPING_SHIFT) |
              (IORT_TRANSLATION_TYPE_NESTED << IORT_TRANSLATION_TYPE_SHIFT) |
              (2))>;
          NumIDs = <1>;
          OutputBase = <0x00000038>;
          Flags = <0>;
          OutputReference = <&APPS_MMU500_SMMU_APP_handle>;
        };
        SIDMappings_4 {
          InputBase = <(
              (IORT_WORLD_ID_NON_SECURE << IORT_WORLD_ID_SHIFT) |
              (IORT_DYNAMIC_MAPPING_NO << IORT_DYNAMIC_MAPPING_SHIFT) |
              (IORT_TRANSLATION_TYPE_NESTED << IORT_TRANSLATION_TYPE_SHIFT) |
              (4))>;
          NumIDs = <1>;
          OutputBase = <0x00000023>;
          Flags = <0>;
          OutputReference = <&APPS_MMU500_SMMU_APP_handle>;
        };
      };
    };
    NAMEDNODE_SDC1_95EMMC {
      Type = <1>;
      Revision = <1>;
      Reserved = <0>;
      NumberofMappings = <1>;
      NodeFlags = <0>;
      CacheCoherency = <0>;
      AllocationHints = <0>;
      Reserved1 = <0>;
      MemAccessFlags = <0>;
      DeviceMemAddressSize = <36>;
      DevObjectName = "SDC1_EMMC";
      SIDMappings {
        SIDMappings_0 {
          InputBase = <(
              (IORT_WORLD_ID_NON_SECURE << IORT_WORLD_ID_SHIFT) |
              (IORT_DYNAMIC_MAPPING_NO << IORT_DYNAMIC_MAPPING_SHIFT) |
              (IORT_TRANSLATION_TYPE_NESTED << IORT_TRANSLATION_TYPE_SHIFT) |
              (0))>;
          NumIDs = <1>;
          OutputBase = <0x00000520>;
          Flags = <0>;
          OutputReference = <&APPS_MMU500_SMMU_APP_handle>;
        };
      };
    };
    NAMEDNODE_SDC2 {
      Type = <1>;
      Revision = <1>;
      Reserved = <0>;
      NumberofMappings = <1>;
      NodeFlags = <0>;
      CacheCoherency = <0>;
      AllocationHints = <0>;
      Reserved1 = <0>;
      MemAccessFlags = <0>;
      DeviceMemAddressSize = <36>;
      DevObjectName = "SDC2";
      SIDMappings {
        SIDMappings_0 {
          InputBase = <(
              (IORT_WORLD_ID_NON_SECURE << IORT_WORLD_ID_SHIFT) |
              (IORT_DYNAMIC_MAPPING_NO << IORT_DYNAMIC_MAPPING_SHIFT) |
              (IORT_TRANSLATION_TYPE_NESTED << IORT_TRANSLATION_TYPE_SHIFT) |
              (0))>;
          NumIDs = <1>;
          OutputBase = <0x00000540>;
          Flags = <0>;
          OutputReference = <&APPS_MMU500_SMMU_APP_handle>;
        };
      };
    };
    NAMEDNODE_Sensors {
      Type = <1>;
      Revision = <1>;
      Reserved = <0>;
      NumberofMappings = <2>;
      NodeFlags = <0>;
      CacheCoherency = <0>;
      AllocationHints = <0>;
      Reserved1 = <0>;
      MemAccessFlags = <0>;
      DeviceMemAddressSize = <36>;
      DevObjectName = "SENSORS";
      SIDMappings {
        SIDMappings_2 {
          InputBase = <(
              (IORT_WORLD_ID_NON_SECURE << IORT_WORLD_ID_SHIFT) |
              (IORT_DYNAMIC_MAPPING_NO << IORT_DYNAMIC_MAPPING_SHIFT) |
              (IORT_TRANSLATION_TYPE_NESTED << IORT_TRANSLATION_TYPE_SHIFT) |
              (2))>;
          NumIDs = <1>;
          OutputBase = <0x000010c3>;
          Flags = <0>;
          OutputReference = <&APPS_MMU500_SMMU_APP_handle>;
        };
        SIDMappings_3 {
          InputBase = <(
              (IORT_WORLD_ID_NON_SECURE << IORT_WORLD_ID_SHIFT) |
              (IORT_DYNAMIC_MAPPING_NO << IORT_DYNAMIC_MAPPING_SHIFT) |
              (IORT_TRANSLATION_TYPE_NESTED << IORT_TRANSLATION_TYPE_SHIFT) |
              (3))>;
          NumIDs = <1>;
          OutputBase = <0x000010d6>;
          Flags = <0>;
          OutputReference = <&APPS_MMU500_SMMU_APP_handle>;
        };
      };
    };
    NAMEDNODE_UFS_95MEM {
      Type = <1>;
      Revision = <1>;
      Reserved = <0>;
      NumberofMappings = <1>;
      NodeFlags = <0>;
      CacheCoherency = <0>;
      AllocationHints = <0>;
      Reserved1 = <0>;
      MemAccessFlags = <0>;
      DeviceMemAddressSize = <36>;
      DevObjectName = "UFS_MEM";
      SIDMappings {
        SIDMappings_0 {
          InputBase = <(
              (IORT_WORLD_ID_NON_SECURE << IORT_WORLD_ID_SHIFT) |
              (IORT_DYNAMIC_MAPPING_NO << IORT_DYNAMIC_MAPPING_SHIFT) |
              (IORT_TRANSLATION_TYPE_NESTED << IORT_TRANSLATION_TYPE_SHIFT) |
              (0))>;
          NumIDs = <1>;
          OutputBase = <0x00000060>;
          Flags = <0>;
          OutputReference = <&APPS_MMU500_SMMU_APP_handle>;
        };
      };
    };
    NAMEDNODE_USB3 {
      Type = <1>;
      Revision = <1>;
      Reserved = <0>;
      NumberofMappings = <1>;
      NodeFlags = <0>;
      CacheCoherency = <0>;
      AllocationHints = <0>;
      Reserved1 = <0>;
      MemAccessFlags = <0>;
      DeviceMemAddressSize = <36>;
      DevObjectName = "USB3";
      SIDMappings {
        SIDMappings_0 {
          InputBase = <(
              (IORT_WORLD_ID_NON_SECURE << IORT_WORLD_ID_SHIFT) |
              (IORT_DYNAMIC_MAPPING_NO << IORT_DYNAMIC_MAPPING_SHIFT) |
              (IORT_TRANSLATION_TYPE_NESTED << IORT_TRANSLATION_TYPE_SHIFT) |
              (0))>;
          NumIDs = <1>;
          OutputBase = <0x00000040>;
          Flags = <0>;
          OutputReference = <&APPS_MMU500_SMMU_APP_handle>;
        };
      };
    };
    NAMEDNODE_Video {
      Type = <1>;
      Revision = <1>;
      Reserved = <0>;
      NumberofMappings = <5>;
      NodeFlags = <0>;
      CacheCoherency = <0>;
      AllocationHints = <0>;
      Reserved1 = <0>;
      MemAccessFlags = <0>;
      DeviceMemAddressSize = <36>;
      DevObjectName = "VIDEO";
      SIDMappings {
        SIDMappings_0 {
          InputBase = <(
              (IORT_WORLD_ID_NON_SECURE << IORT_WORLD_ID_SHIFT) |
              (IORT_DYNAMIC_MAPPING_NO << IORT_DYNAMIC_MAPPING_SHIFT) |
              (IORT_TRANSLATION_TYPE_NESTED << IORT_TRANSLATION_TYPE_SHIFT) |
              (0))>;
          NumIDs = <1>;
          OutputBase = <0x00001960>;
          Flags = <0>;
          OutputReference = <&APPS_MMU500_SMMU_APP_handle>;
        };
        SIDMappings_1 {
          InputBase = <(
              (IORT_WORLD_ID_NON_SECURE << IORT_WORLD_ID_SHIFT) |
              (IORT_DYNAMIC_MAPPING_NO << IORT_DYNAMIC_MAPPING_SHIFT) |
              (IORT_TRANSLATION_TYPE_NESTED << IORT_TRANSLATION_TYPE_SHIFT) |
              (1))>;
          NumIDs = <1>;
          OutputBase = <0x00041961>;
          Flags = <0>;
          OutputReference = <&APPS_MMU500_SMMU_APP_handle>;
        };
        SIDMappings_3 {
          InputBase = <(
              (IORT_WORLD_ID_NON_SECURE << IORT_WORLD_ID_SHIFT) |
              (IORT_DYNAMIC_MAPPING_NO << IORT_DYNAMIC_MAPPING_SHIFT) |
              (IORT_TRANSLATION_TYPE_NESTED << IORT_TRANSLATION_TYPE_SHIFT) |
              (3))>;
          NumIDs = <1>;
          OutputBase = <0x00001963>;
          Flags = <0>;
          OutputReference = <&APPS_MMU500_SMMU_APP_handle>;
        };
        SIDMappings_4 {
          InputBase = <(
              (IORT_WORLD_ID_NON_SECURE << IORT_WORLD_ID_SHIFT) |
              (IORT_DYNAMIC_MAPPING_NO << IORT_DYNAMIC_MAPPING_SHIFT) |
              (IORT_TRANSLATION_TYPE_NESTED << IORT_TRANSLATION_TYPE_SHIFT) |
              (4))>;
          NumIDs = <1>;
          OutputBase = <0x00001964>;
          Flags = <0>;
          OutputReference = <&APPS_MMU500_SMMU_APP_handle>;
        };
        SIDMappings_5 {
          InputBase = <(
              (IORT_WORLD_ID_NON_SECURE << IORT_WORLD_ID_SHIFT) |
              (IORT_DYNAMIC_MAPPING_NO << IORT_DYNAMIC_MAPPING_SHIFT) |
              (IORT_TRANSLATION_TYPE_NESTED << IORT_TRANSLATION_TYPE_SHIFT) |
              (5))>;
          NumIDs = <1>;
          OutputBase = <0x00001967>;
          Flags = <0>;
          OutputReference = <&APPS_MMU500_SMMU_APP_handle>;
        };
      };
    };
  };
};
